# STM32F40x register map
File version: 1.5
Registers are 32-bit, read-write, reset 0x0 unless marked. A register's access mark holds for its fields unless they carry their own. Offsets are from the block's base; [hi:lo] are bit positions; {n}, {i} and the like mark numbered series.

## TIM1（定时器1(高级定时器)） — 高级定时器：计数/比较/PWM/输入捕获 | Advanced-timers
Base 0x40010000
Same registers: TIM8（定时器8(高级定时器)） 0x40010400
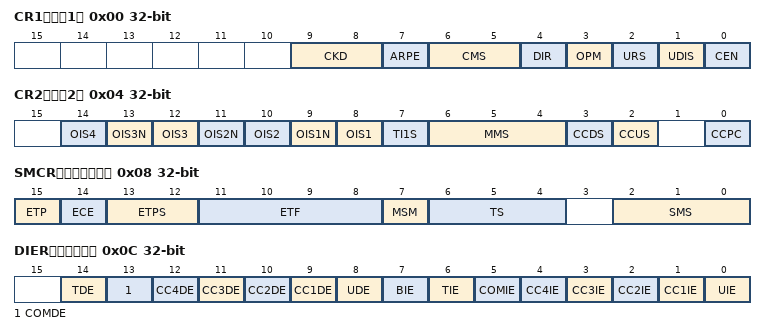
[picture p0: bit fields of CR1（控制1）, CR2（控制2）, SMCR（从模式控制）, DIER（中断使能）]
0x00 CR1（控制1） — 控制1：计数器使能/方向/对齐/分频 | control register 1
  [9:8] CKD — Clock division
  [7] ARPE — Auto-reload preload enable
  [6:5] CMS — Center-aligned mode selection
  [4] DIR — Direction
  [3] OPM — One-pulse mode
  [2] URS — Update request source
  [1] UDIS — Update disable
  [0] CEN — Counter enable
0x04 CR2（控制2） — 控制2：主从模式/输出空闲状态 | control register 2
  [2n+6] OIS{n} (n=1..4) — Output Idle state {n}
  [13] OIS3N — Output Idle state 3
  [11] OIS2N — Output Idle state 2
  [9] OIS1N — Output Idle state 1
  [7] TI1S — TI1 selection
  [6:4] MMS — Master mode selection
  [3] CCDS — Capture/compare DMA selection
  [2] CCUS — Capture/compare control update selection
  [0] CCPC — Capture/compare preloaded control
0x08 SMCR（从模式控制） — 从模式控制：触发/门控/外部时钟选择 | slave mode control register
  [15] ETP — External trigger polarity
  [14] ECE — External clock enable
  [13:12] ETPS — External trigger prescaler
  [11:8] ETF — External trigger filter
  [7] MSM — Master/Slave mode
  [6:4] TS — Trigger selection
  [2:0] SMS — Slave mode selection
0x0C DIER（中断使能） — DMA/中断使能：更新/捕获/触发 | DMA/Interrupt enable register
  [14] TDE — Trigger DMA request enable
  [13] COMDE — COM DMA request enable
  [n+8] CC{n}DE (n=1..4) — Capture/Compare {n} DMA request enable
  [8] UDE — Update DMA request enable
  [7] BIE — Break interrupt enable
  [6] TIE — Trigger interrupt enable
  [5] COMIE — COM interrupt enable
  [n] CC{n}IE (n=1..4) — Capture/Compare {n} interrupt enable
  [0] UIE — Update interrupt enable
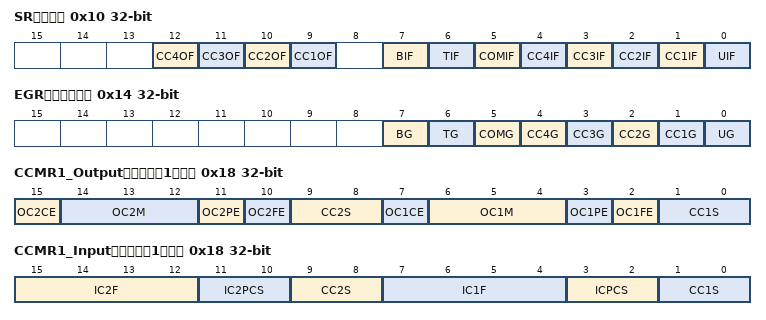
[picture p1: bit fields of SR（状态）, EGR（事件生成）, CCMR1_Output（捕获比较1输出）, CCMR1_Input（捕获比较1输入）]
0x10 SR（状态） — 状态：更新/捕获/触发 等中断标志 | status register
  [12] CC4OF — Capture/Compare 4 overcapture flag
  [11] CC3OF — Capture/Compare 3 overcapture flag
  [10] CC2OF — Capture/compare 2 overcapture flag
  [9] CC1OF — Capture/Compare 1 overcapture flag
  [7] BIF — Break interrupt flag
  [6] TIF — Trigger interrupt flag
  [5] COMIF — COM interrupt flag
  [4] CC4IF — Capture/Compare 4 interrupt flag
  [3] CC3IF — Capture/Compare 3 interrupt flag
  [2] CC2IF — Capture/Compare 2 interrupt flag
  [1] CC1IF — Capture/compare 1 interrupt flag
  [0] UIF — Update interrupt flag
0x14 EGR（事件生成） wo — 事件生成：软件触发更新/捕获事件 | event generation register
  [7] BG — Break generation
  [6] TG — Trigger generation
  [5] COMG — Capture/Compare control update generation
  [n] CC{n}G (n=1..4) — Capture/compare {n} generation
  [0] UG — Update generation
0x18 CCMR1_Output（捕获比较1输出） — 通道1/2 输出比较模式 | capture/compare mode register 1 (output mode)
  [15] OC2CE — Output Compare 2 clear enable
  [14:12] OC2M — Output Compare 2 mode
  [11] OC2PE — Output Compare 2 preload enable
  [10] OC2FE — Output Compare 2 fast enable
  [9:8] CC2S — Capture/Compare 2 selection
  [7] OC1CE — Output Compare 1 clear enable
  [6:4] OC1M — Output Compare 1 mode
  [3] OC1PE — Output Compare 1 preload enable
  [2] OC1FE — Output Compare 1 fast enable
  [1:0] CC1S — Capture/Compare 1 selection
0x18 CCMR1_Input（捕获比较1输入） (alternate view of CCMR1_Output) — 通道1/2 输入捕获模式 | capture/compare mode register 1 (input mode)
  [15:12] IC2F — Input capture 2 filter
  [11:10] IC2PCS — Input capture 2 prescaler
  [9:8] CC2S — Capture/Compare 2 selection
  [7:4] IC1F — Input capture 1 filter
  [3:2] ICPCS — Input capture 1 prescaler
  [1:0] CC1S — Capture/Compare 1 selection
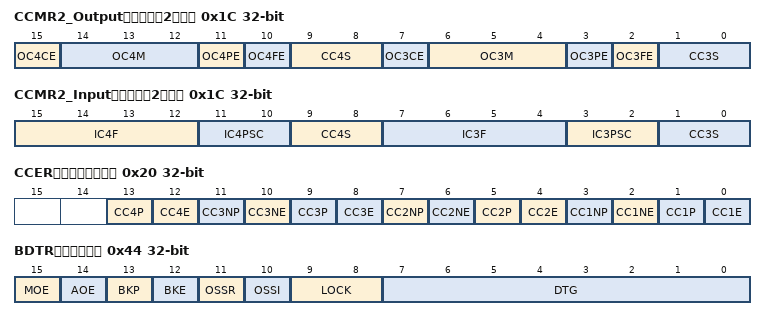
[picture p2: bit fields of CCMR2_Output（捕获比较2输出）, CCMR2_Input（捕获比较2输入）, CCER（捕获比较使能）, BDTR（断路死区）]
0x1C CCMR2_Output（捕获比较2输出） — 通道3/4 输出比较模式 | capture/compare mode register 2 (output mode)
  [15] OC4CE — Output compare 4 clear enable
  [14:12] OC4M — Output compare 4 mode
  [11] OC4PE — Output compare 4 preload enable
  [10] OC4FE — Output compare 4 fast enable
  [9:8] CC4S — Capture/Compare 4 selection
  [7] OC3CE — Output compare 3 clear enable
  [6:4] OC3M — Output compare 3 mode
  [3] OC3PE — Output compare 3 preload enable
  [2] OC3FE — Output compare 3 fast enable
  [1:0] CC3S — Capture/Compare 3 selection
0x1C CCMR2_Input（捕获比较2输入） (alternate view of CCMR2_Output) — 通道3/4 输入捕获模式 | capture/compare mode register 2 (input mode)
  [15:12] IC4F — Input capture 4 filter
  [11:10] IC4PSC — Input capture 4 prescaler
  [9:8] CC4S — Capture/Compare 4 selection
  [7:4] IC3F — Input capture 3 filter
  [3:2] IC3PSC — Input capture 3 prescaler
  [1:0] CC3S — Capture/compare 3 selection
0x20 CCER（捕获比较使能） — 各通道 使能/极性/方向 | capture/compare enable register
  [13] CC4P — Capture/Compare 3 output Polarity
  [4n-4] CC{n}E (n=1..4) — Capture/Compare {n} output enable
  [11] CC3NP — Capture/Compare 3 output Polarity
  [10] CC3NE — Capture/Compare 3 complementary output enable
  [9] CC3P — Capture/Compare 3 output Polarity
  [7] CC2NP — Capture/Compare 2 output Polarity
  [6] CC2NE — Capture/Compare 2 complementary output enable
  [5] CC2P — Capture/Compare 2 output Polarity
  [3] CC1NP — Capture/Compare 1 output Polarity
  [2] CC1NE — Capture/Compare 1 complementary output enable
  [1] CC1P — Capture/Compare 1 output Polarity
0x24 CNT（计数器） — 当前计数值 | counter
  [15:0] CNT — counter value
0x28 PSC（预分频） — 计数器时钟预分频 | prescaler
  [15:0] PSC — Prescaler value
0x2C ARR（自动重装） — 自动重装载值（周期） | auto-reload register
  [15:0] ARR — Auto-reload value
0x30 RCR（重复计数） — 重复计数器（高级定时器） | repetition counter register
  [7:0] REP — Repetition counter value
0x34 CCR1（捕获比较1） — 通道1 比较值/捕获值 | capture/compare register 1
  [15:0] CCR1 — Capture/Compare 1 value
0x38 CCR2（捕获比较2） — 通道2 比较值/捕获值 | capture/compare register 2
  [15:0] CCR2 — Capture/Compare 2 value
0x3C CCR3（捕获比较3） — 通道3 比较值/捕获值 | capture/compare register 3
  [15:0] CCR3 — Capture/Compare value
0x40 CCR4（捕获比较4） — 通道4 比较值/捕获值 | capture/compare register 4
  [15:0] CCR4 — Capture/Compare value
0x44 BDTR（断路死区） — 死区/刹车保护（高级定时器） | break and dead-time register
  [15] MOE — Main output enable
  [14] AOE — Automatic output enable
  [13] BKP — Break polarity
  [12] BKE — Break enable
  [11] OSSR — Off-state selection for Run mode
  [10] OSSI — Off-state selection for Idle mode
  [9:8] LOCK — Lock configuration
  [7:0] DTG — Dead-time generator setup
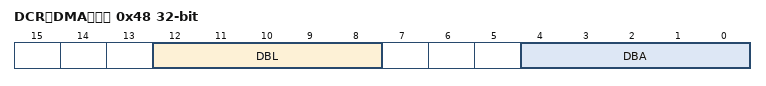
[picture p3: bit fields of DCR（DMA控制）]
0x48 DCR（DMA控制） — DMA 突发访问配置 | DMA control register
  [12:8] DBL — DMA burst length
  [4:0] DBA — DMA base address
0x4C DMAR（DMA地址） — DMA 连续访问数据 | DMA address for full transfer
  [15:0] DMAB — DMA register for burst accesses
